VERSION ""

NS_ :

BS_:

BU_: LIM SME VCU

BO_ 3221225472 VECTOR__INDEPENDENT_SIG_MSG: 0 Vector__XXX
 SG_ FC_Contactor_Test : 0|1@0+ (1,0) [0|1] "" Vector__XXX
 SG_ Displayed_SOC : 0|8@1+ (0.5,0) [0|100] "%" Vector__XXX
 SG_ CV_Setpoint : 0|12@1+ (0.1,0) [0|409.4] "Volts" Vector__XXX
 SG_ New_Signal_79 : 16|8@1+ (1,0) [0|0] "" Vector__XXX

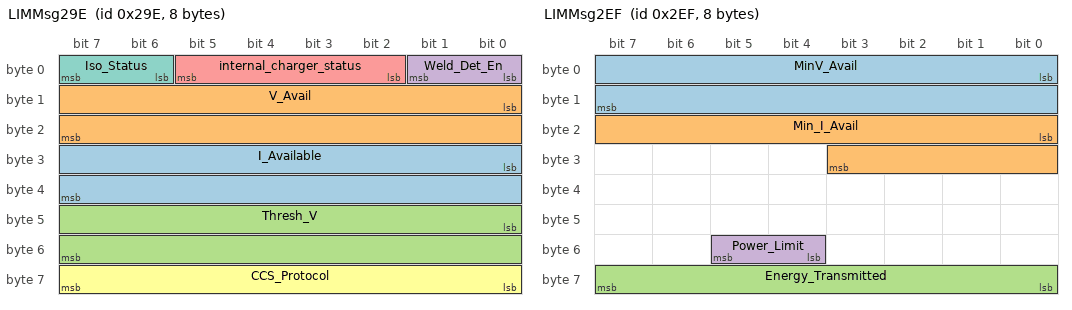
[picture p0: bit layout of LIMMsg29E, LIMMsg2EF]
BO_ 670 LIMMsg29E: 8 LIM
 SG_ I_Available : 24|16@1+ (0.1,0) [-500|500] "Amps" Vector__XXX
 SG_ V_Avail : 8|16@1+ (0.1,0) [0|1000] "Volts" Vector__XXX
 SG_ Thresh_V : 40|16@1+ (0.1,0) [0|600] "V" Vector__XXX
 SG_ Weld_Det_En : 0|2@1+ (1,0) [0|4] "" Vector__XXX
 SG_ internal_charger_status : 2|4@1+ (1,0) [0|16] "" Vector__XXX
 SG_ CCS_Protocol : 56|8@1+ (1,0) [0|255] "" Vector__XXX
 SG_ Iso_Status : 6|2@1+ (1,0) [0|3] "" Vector__XXX

BO_ 751 LIMMsg2EF: 8 LIM
 SG_ MinV_Avail : 0|16@1+ (0.1,0) [0|1000] "Volts" Vector__XXX
 SG_ Min_I_Avail : 16|12@1+ (0.1,0) [0|410] "A" Vector__XXX
 SG_ Energy_Transmitted : 56|8@1+ (0.25,0) [0|63] "kWh" Vector__XXX
 SG_ Power_Limit : 52|2@1+ (1,0) [0|2] "" Vector__XXX

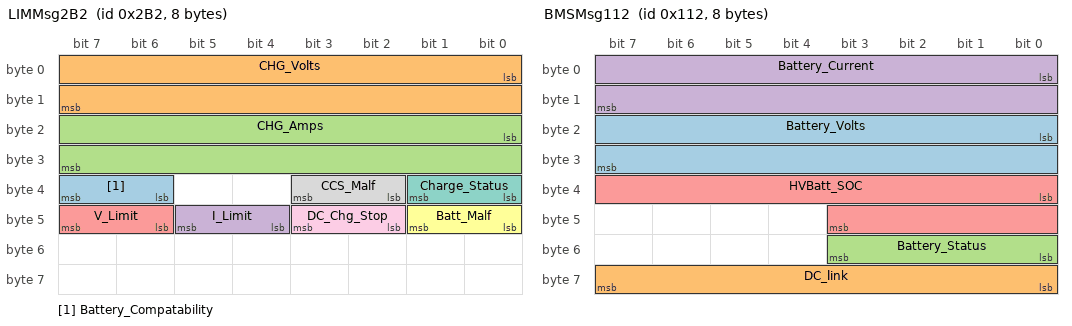
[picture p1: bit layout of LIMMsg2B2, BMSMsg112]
BO_ 690 LIMMsg2B2: 8 LIM
 SG_ Battery_Compatability : 38|2@1+ (1,0) [0|4] "" Vector__XXX
 SG_ CHG_Volts : 0|16@1+ (0.1,0) [0|1] "Volts" Vector__XXX
 SG_ CHG_Amps : 16|16@1+ (0.1,0) [-500|500] "Amps" Vector__XXX
 SG_ I_Limit : 44|2@1+ (1,0) [0|1] "" Vector__XXX
 SG_ V_Limit : 46|2@1+ (1,0) [0|3] "" Vector__XXX
 SG_ Batt_Malf : 40|2@1+ (1,0) [0|3] "" Vector__XXX
 SG_ Charge_Status : 32|2@1+ (1,0) [0|3] "" Vector__XXX
 SG_ CCS_Malf : 34|2@1+ (1,0) [0|3] "" Vector__XXX
 SG_ DC_Chg_Stop : 42|2@1+ (1,0) [0|3] "" Vector__XXX

BO_ 948 LIMMsg3B4: 8 LIM
 SG_ Pilot_Current : 0|8@1+ (1,0) [0|63] "Amps" Vector__XXX
 SG_ Cable_Current : 8|8@1+ (1,0) [0|63] "Amps" Vector__XXX
 SG_ FC_Voltage : 56|8@1+ (2,0) [0|500] "Volts" Vector__XXX
 SG_ Pilot_Status : 32|3@1+ (1,0) [0|1] "" Vector__XXX
 SG_ PP_Status : 23|2@1+ (1,0) [0|1] "" Vector__XXX
 SG_ CP_Lock_Status : 26|2@1+ (1,0) [0|1] "" Vector__XXX
 SG_ CHG_Flap_Status : 24|2@1+ (1,0) [0|4] "" Vector__XXX
 SG_ Plug_Connection : 37|2@1+ (1,0) [0|4] "" Vector__XXX
 SG_ Charge_End_Sig : 20|2@1+ (1,0) [0|4] "" Vector__XXX
 SG_ HW_Charger_EN : 22|2@1+ (1,0) [0|1] "" Vector__XXX
 SG_ CCS_Plug : 35|2@1+ (1,0) [0|1] "" Vector__XXX
 SG_ Charging_Type : 48|8@1+ (1,0) [0|1] "" Vector__XXX
 SG_ DC_Chg_Volts : 39|9@1+ (2,0) [0|1000] "V" Vector__XXX

BO_ 274 BMSMsg112: 8 SME
 SG_ Battery_Volts : 16|16@1+ (0.1,0) [0|500] "Volts" Vector__XXX
 SG_ DC_link : 56|8@1+ (4,0) [0|1000] "Volts" Vector__XXX
 SG_ Battery_Status : 48|4@1+ (1,0) [0|16] "" Vector__XXX
 SG_ Battery_Current : 0|16@1+ (0.1,-819.2) [0|819] "Amps" Vector__XXX
 SG_ HVBatt_SOC : 32|12@1+ (0.1,0) [0|100] "%" Vector__XXX

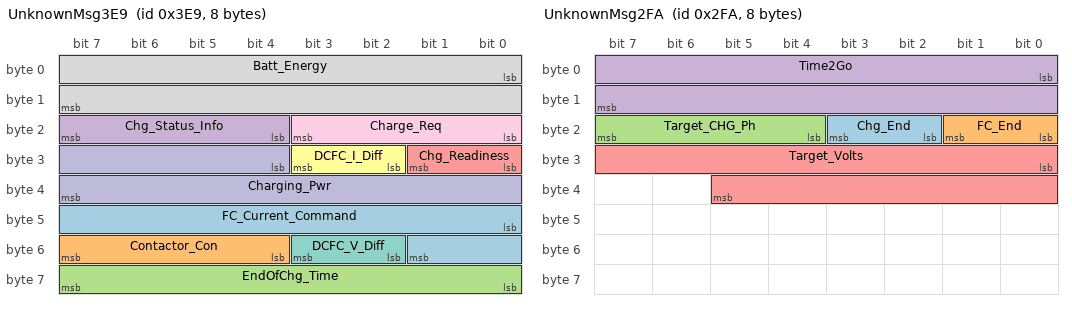
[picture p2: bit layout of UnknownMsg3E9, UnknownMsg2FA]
BO_ 1001 UnknownMsg3E9: 8 VCU
 SG_ FC_Current_Command : 40|10@1- (1,0) [-500|500] "Amps" Vector__XXX
 SG_ Contactor_Con : 52|4@1+ (1,0) [0|16] "" Vector__XXX
 SG_ EndOfChg_Time : 56|8@1+ (1,0) [0|255] "Mins" Vector__XXX
 SG_ Chg_Status_Info : 20|4@1+ (1,0) [0|3] "" Vector__XXX
 SG_ Chg_Readiness : 24|2@1+ (1,0) [0|3] "" Vector__XXX
 SG_ DCFC_I_Diff : 26|2@1+ (1,0) [0|3] "" Vector__XXX
 SG_ DCFC_V_Diff : 50|2@1+ (1,0) [0|3] "" Vector__XXX
 SG_ Batt_Energy : 0|16@1+ (1,0) [0|65534] "Wh" Vector__XXX
 SG_ Charge_Req : 16|4@1+ (1,0) [0|16] "" Vector__XXX
 SG_ Charging_Pwr : 28|12@1+ (25,0) [0|102350] "Watts" Vector__XXX

BO_ 762 UnknownMsg2FA: 8 VCU
 SG_ Chg_End : 18|2@1+ (1,0) [0|1] "" Vector__XXX
 SG_ FC_End : 16|2@1+ (1,0) [0|1] "" Vector__XXX
 SG_ Target_CHG_Ph : 20|4@1+ (1,0) [0|1] "" Vector__XXX
 SG_ Time2Go : 0|16@1+ (1,0) [0|65534] "Mins" Vector__XXX
 SG_ Target_Volts : 24|14@1+ (0.1,0) [0|1000] "V"  LIM

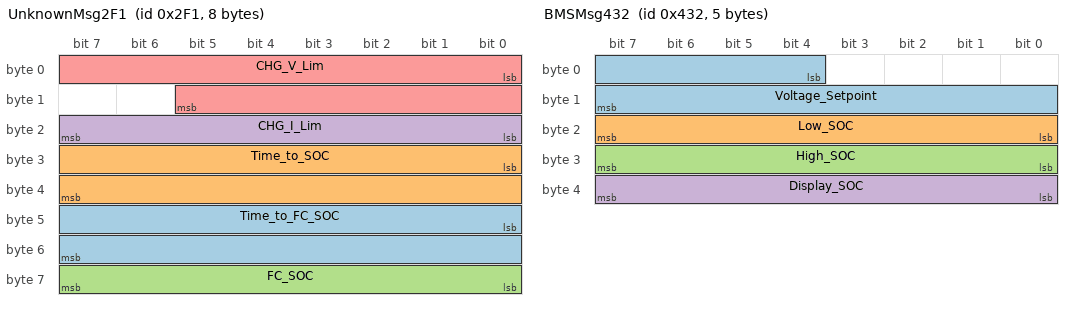
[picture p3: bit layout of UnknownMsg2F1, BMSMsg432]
BO_ 753 UnknownMsg2F1: 8 VCU
 SG_ Time_to_FC_SOC : 40|16@1+ (10,0) [0|655320] "Secs" Vector__XXX
 SG_ Time_to_SOC : 24|16@1+ (10,0) [0|655320] "Secs" Vector__XXX
 SG_ FC_SOC : 56|8@1+ (0.5,0) [0|100] "%" Vector__XXX
 SG_ CHG_I_Lim : 16|8@1+ (1,0) [0|254] "Amps"  LIM
 SG_ CHG_V_Lim : 0|14@1- (0.1,0) [0|1000] "Volts" Vector__XXX

BO_ 1073 BMSMsg431: 7 SME
 SG_ Serv_Dis_Status : 0|2@1+ (1,0) [0|1] "" Vector__XXX
 SG_ Total_Battery : 40|12@1+ (0.02,0) [0|82] "kWh" Vector__XXX

BO_ 1074 BMSMsg432: 5 SME
 SG_ Voltage_Setpoint : 4|12@1+ (0.1,0) [0|410] "Volts"  LIM
 SG_ Low_SOC : 16|8@1+ (0.5,0) [0|100] "%"  LIM
 SG_ High_SOC : 24|8@1+ (0.5,0) [0|100] "%"  LIM
 SG_ Display_SOC : 32|8@1+ (0.5,0) [0|100] "%"  LIM

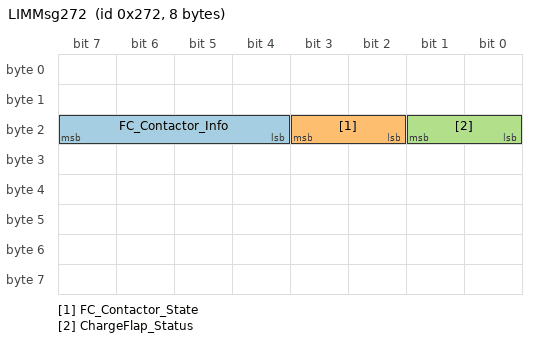
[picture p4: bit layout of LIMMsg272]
BO_ 626 LIMMsg272: 8 LIM
 SG_ FC_Contactor_Info : 20|4@1+ (1,0) [0|15] "" Vector__XXX
 SG_ FC_Contactor_State : 18|2@1+ (1,0) [0|3] "" Vector__XXX
 SG_ ChargeFlap_Status : 16|2@1+ (1,0) [0|4] "" Vector__XXX

BO_ 808 UnknownMsg328: 6 VCU
 SG_ Seconds_ctr : 0|32@1+ (1,0) [0|2704] "S"  LIM
 SG_ Day_ctr : 32|16@1+ (1,0) [0|65534] "Days"  LIM

BO_ 303 UnknownMsg12f: 8 VCU
 SG_ ST_KL : 16|4@1+ (1,0) [0|15] "" Vector__XXX

BO_ 1000 UnknownMsg3e8: 2 VCU
 SG_ RQ_Diag : 2|2@1+ (1,0) [0|4] ""  LIM

BO_ 764 UnknownMsg2fc: 8 VCU
 SG_ lock_button : 22|2@1+ (1,0) [0|4] ""  LIM

BO_ 823 LIMMsg337: 2 LIM
 SG_ Hook_Pos : 0|2@1+ (1,0) [0|3] "" Vector__XXX
 SG_ Hook_Lock : 2|2@1+ (1,0) [0|3] "" Vector__XXX

BO_ 816 UnknownMsg330: 8 VCU
 SG_ Odometer : 0|24@1+ (1,0) [0|16777200] "km" Vector__XXX

BO_ 1072 BMSMsg430: 8 SME

BO_ 506 BMSMsg1FA: 8 SME

BO_ 1037 BMSMsg40D: 8 SME

BO_ 767 BMSMsg2FF: 6 SME

BO_ 569 BMSMsg239: 8 SME

BO_ 701 BMSMsg2BD: 8 SME

BO_ 757 BMSMsg2F5: 8 SME

BO_ 962 BMSMsg3C2: 8 SME

BO_ 1003 BMSMsg3EB: 8 SME

BO_ 867 BMSMsg363: 8 SME

BO_ 1287 BMSMsg507: 8 SME

BO_ 1415 BMSMsg587: 8 SME

BO_ 1052 BMSMsg41C: 2 SME
 SG_ Frame0_41C : 0|8@1+ (1,0) [0|0] "" Vector__XXX
 SG_ Frame1_41C : 8|8@1+ (1,0) [0|0] "" Vector__XXX

BO_ 1543 BMSMsg607: 8 SME

CM_ BU_ SME "BMS";
CM_ BU_ VCU "Lim Command";
CM_ BO_ 3221225472 "This is a message for not used signals, created by Vector CANdb++ DBC OLE DB Provider.";
CM_ BO_ 670 "Only broadcasted during fastcharging - CCS charger specs ";
CM_ BO_ 751 "- Min available voltage from the ccs charger";
CM_ BO_ 690 "Only broadcasted during fastcharging - Voltage/current from charger";
CM_ BO_ 948 "200ms";
CM_ BO_ 274 "10ms - BMS status";
CM_ BO_ 1001 "200ms - Main LIM control
";
CM_ BO_ 762 "80ms<->1s (low interval during CCS start up)  - Lim DC charge command 3";
CM_ BO_ 753 "100ms - Lim DC charge command 2";
CM_ BO_ 1073 "200ms - Battery info";
CM_ BO_ 1074 "200ms - Battery SOC info";
CM_ BO_ 626 "- CCS contactor state and charge flap open/close status";
CM_ BO_ 808 "1000ms - Counter";
CM_ BO_ 303 "100ms - Wake up message";
CM_ BO_ 1000 "1000ms";
CM_ BO_ 764 "100ms - Charge flap control";
CM_ BO_ 816 "200ms - Range info";
CM_ BO_ 1072 "Variable rate - Always brodcasted by 94Ah battery";
CM_ BO_ 506 "1s - Always brodcasted by 94Ah battery";
CM_ BO_ 1037 "1s - Always brodcasted by 94Ah battery";
CM_ BO_ 767 "100ms - Always brodcasted by 94Ah battery";
CM_ BO_ 569 "200ms - Always brodcasted by 94Ah battery";
CM_ BO_ 701 "100ms - Always brodcasted by 94Ah battery";
CM_ BO_ 757 "100ms - Always brodcasted by 94Ah battery";
CM_ BO_ 962 "1s - Always brodcasted by 94Ah battery";
CM_ BO_ 1003 "1s - Always brodcasted by 94Ah battery";
CM_ BO_ 867 "1s - Always brodcasted by 94Ah battery";
CM_ BO_ 1287 "Always brodcasted by 94Ah battery";
CM_ BO_ 1415 "5s - Always brodcasted by 94Ah battery";
CM_ BO_ 1052 "1s - Always brodcasted by 94Ah battery";
CM_ SG_ 1052 Frame0_41C "Static 0xFF";
CM_ SG_ 1052 Frame1_41C "Static 0xFC";
CM_ BO_ 1543 "Always brodcasted by 94Ah battery";
VAL_ 670 Weld_Det_En 0 "Charger_does_not_support_the_EV" 1 "Charger_supports_the_EV_relay_weld" 3 "Signal_unavail" ;
VAL_ 670 internal_charger_status 0 "Not_ready" 1 "Ready" 2 "Switch_off_charger" 3 "Interruption" 4 "Pre_charge" 5 "insulation_monitor" 6 "estop" 7 "Malfunction" 19 "reserved" 20 "reserved" 21 "signal_invalid" ;
VAL_ 670 Iso_Status 0 "invalid" 1 "valid" 2 "error" 3 "invalid_signal" ;
VAL_ 751 Power_Limit 0 "No" 1 "Yes" 3 "Invalid" ;
VAL_ 690 Battery_Compatability 0 "Compatible" 1 "Incompatible" 3 "Signal_error" ;
VAL_ 690 I_Limit 0 "No" 1 "Yes" 3 "Invalid" ;
VAL_ 690 V_Limit 0 "No" 1 "Yes" 3 "Invalid" ;
VAL_ 690 Batt_Malf 0 "No" 1 "Yes" 3 "Invalid" ;
VAL_ 690 Charge_Status 0 "Standby" 1 "Charging" 3 "Invalid" ;
VAL_ 690 CCS_Malf 0 "Normal" 1 "Fail" 3 "Invalid" ;
VAL_ 690 DC_Chg_Stop 0 "Tracking" 1 "Supression" 3 "Invalid" ;
VAL_ 948 FC_Voltage 251 "AC_Charge" 254 "Error" 252 "Not_Available" ;
VAL_ 948 Pilot_Status 0 "No_Pilot" 1 "AC_Not_Ready" 2 "AC_Ready" 3 "Error" 4 "5%_Not_Ready" 5 "5%_Ready" 6 "Pilot_Static" ;
VAL_ 948 PP_Status 0 "Unplugged" 1 "Plug_Inserted" ;
VAL_ 948 CP_Lock_Status 0 "Not_Locked" 1 "Locked" 2 "Error" 3 "Invalid_signal" ;
VAL_ 948 CHG_Flap_Status 0 "not_locked" 1 "locked" 3 "invalid" ;
VAL_ 948 Plug_Connection 0 "None" 1 "Plugged" 2 "Error" 3 "Invalid_Signal" ;
VAL_ 948 Charge_End_Sig 0 "No_Request" 1 "End_Chg_Driver" 2 "End_Chg_CSM" 3 "Invalid" ;
VAL_ 948 HW_Charger_EN 0 "Inactive" 1 "Active" 2 "Error" 3 "Invalid" ;
VAL_ 948 CCS_Plug 0 "Not_Inserted" 1 "Inserted" 2 "Error" 3 "Invalid_Signal" ;
VAL_ 948 Charging_Type 0 "Noen" 1 "AC_Type_1" 2 "AC_Type_2" 3 "DC_Chademo" 4 "DC_CCS_Type_1C" 5 "AC_China" 6 "AC_CCS_Type_1" 7 "AC_CCS_Type_2" 8 "DC_CCS_Type_1" 9 "DC_CCS_Type_2C" ;
VAL_ 948 DC_Chg_Volts 507 "AC_or_Neg" 508 "Inactive" 509 "Not_avail" 510 "Error" 511 "Invalid" ;
VAL_ 274 Battery_Status 5 "Normal" ;
VAL_ 1001 Contactor_Con 0 "Open" 1 "OpenwithDiag" 2 "Close" 21 "Invalid" ;
VAL_ 1001 Chg_Status_Info 0 "No_charge" 1 "Init" 2 "Charge_active" 3 "Charge_pause" 4 "Charge_complete" 5 "Charge_error" 15 "Invalid" ;
VAL_ 1001 Chg_Readiness 0 "Not_Ready" 1 "Ready" 3 "Unavailable" ;
VAL_ 1001 Charge_Req 0 "No_Charge" 1 "PlugCharge" 2 "Timer" ;
VAL_ 762 Target_CHG_Ph 0 "Standby" 1 "Initialisation" 2 "Subpoena" 3 "Energy_Transfer" 4 "Turn_Off" 15 "Reserved" 14 "Reserved" 9 "Cable_Test" ;
VAL_ 626 FC_Contactor_Info 15 "Error" 7 "Weld Fault, Port Unenergized" 6 "Unexpected Voltage at Port" 5 "Second Contactor Welded" 4 "First Contactor Welded" 3 "Cont Weld cannot be carried out" 2 "Cont Weld test ongogin" 1 "Cont Weld test not carried out" 0 "DC Charge Port Okay" ;
VAL_ 626 FC_Contactor_State 3 "Invalid Signal" 2 "Error" 1 "DC Contactor Closed" 0 "DC Contactor Open" ;
VAL_ 626 ChargeFlap_Status 0 "closed" 1 "open" 2 "error" 3 "invalid" ;
VAL_ 303 ST_KL 0 "No Description" ;
VAL_ 1000 RQ_Diag 0 "No_Reset" 2 "Reset" ;
VAL_ 764 lock_button 0 "no_op" 1 "unlock" 2 "lock" 3 "invalid" ;
VAL_ 823 Hook_Pos 0 "Inactive" 1 "Active" 3 "Invalid" ;
VAL_ 823 Hook_Lock 0 "Not_Locked" 1 "Locked" 3 "Invalid" ;
